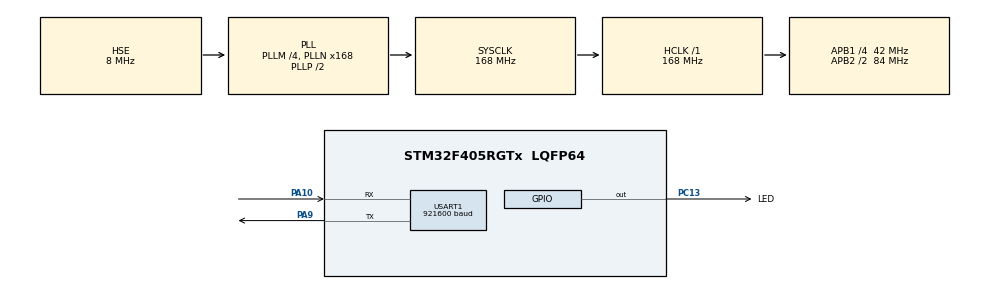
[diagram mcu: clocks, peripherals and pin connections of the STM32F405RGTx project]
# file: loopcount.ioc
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Mcu.Family=STM32F4
Mcu.Name=STM32F405RGTx
Mcu.Package=LQFP64
NVIC.PriorityGroup=NVIC_PRIORITYGROUP_4
NVIC.USART1_IRQn=true\:0\:0\:false\:false\:true\:true\:true
PA10.Mode=Asynchronous
PA10.Signal=USART1_RX
PA13.Mode=Serial_Wire
PA13.Signal=SYS_JTMS-SWDIO
PA14.Mode=Serial_Wire
PA14.Signal=SYS_JTCK-SWCLK
PA9.Mode=Asynchronous
PA9.Signal=USART1_TX
PC13-ANTI_TAMP.GPIO_Label=LED
PC13-ANTI_TAMP.GPIO_ModeDefaultOutputPP=GPIO_MODE_OUTPUT_OD
PC13-ANTI_TAMP.PinState=GPIO_PIN_SET
PC13-ANTI_TAMP.Signal=GPIO_Output
PH0-OSC_IN.Mode=HSE-External-Oscillator
PH0-OSC_IN.Signal=RCC_OSC_IN
PH1-OSC_OUT.Mode=HSE-External-Oscillator
PH1-OSC_OUT.Signal=RCC_OSC_OUT
ProjectManager.HeapSize=0x200
ProjectManager.StackSize=0x400
ProjectManager.TargetToolchain=STM32CubeIDE
RCC.48MHZClocksFreq_Value=84000000
RCC.AHBFreq_Value=168000000
RCC.APB1CLKDivider=RCC_HCLK_DIV4
RCC.APB1Freq_Value=42000000
RCC.APB1TimFreq_Value=84000000
RCC.APB2CLKDivider=RCC_HCLK_DIV2
RCC.APB2Freq_Value=84000000
RCC.APB2TimFreq_Value=168000000
RCC.CortexFreq_Value=168000000
RCC.DATA_CACHE_ENABLE=1
RCC.HCLKFreq_Value=168000000
RCC.HSE_VALUE=8000000
RCC.HSI_VALUE=16000000
RCC.INSTRUCTION_CACHE_ENABLE=1
RCC.LSE_VALUE=32768
RCC.PLLM=4
RCC.PLLN=168
RCC.PLLSourceVirtual=RCC_PLLSOURCE_HSE
RCC.PREFETCH_ENABLE=1
RCC.SYSCLKFreq_VALUE=168000000
RCC.SYSCLKSource=RCC_SYSCLKSOURCE_PLLCLK
RCC.VCOOutputFreq_Value=336000000
USART1.BaudRate=921600
USART1.VirtualMode=VM_ASYNC
board=custom

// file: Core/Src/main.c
/* USER CODE BEGIN Header */
/**
  ******************************************************************************
  * @file           : main.c
  * @brief          : Main program body
  ******************************************************************************
  * @attention
  *
  * <h2><center>&copy; Copyright (c) 2021 STMicroelectronics.
  * All rights reserved.</center></h2>
  *
  * This software component is licensed by ST under BSD 3-Clause license,
  * the "License"; You may not use this file except in compliance with the
  * License. You may obtain a copy of the License at:
  *                        opensource.org/licenses/BSD-3-Clause
  *
  ******************************************************************************
  */
/* USER CODE END Header */
#include "main.h"

/* USER CODE BEGIN Includes */
#include "stdio.h"
/* USER CODE END Includes */

UART_HandleTypeDef huart1;

void SystemClock_Config(void);
static void MX_GPIO_Init(void);
static void MX_USART1_UART_Init(void);

/* USER CODE BEGIN 0 */
// Send printf to uart1

int _write(int fd, char* ptr, int len) {
  HAL_StatusTypeDef hstatus;

  if (fd == 1 || fd == 2) {
    hstatus = HAL_UART_Transmit(&huart1, (uint8_t *) ptr, len, HAL_MAX_DELAY);
    if (hstatus == HAL_OK)
      return len;
    else
      return -1;
  }
  return -1;
}

/* USER CODE END 0 */

int main(void)
{

  /* MCU Configuration--------------------------------------------------------*/

  /* Reset of all peripherals, Initializes the Flash interface and the Systick. */
  HAL_Init();

  /* Configure the system clock */
  SystemClock_Config();

  /* Initialize all configured peripherals */
  MX_GPIO_Init();
  MX_USART1_UART_Init();
  /* USER CODE BEGIN 2 */
  printf("Loopcount start!\n");
  /* USER CODE END 2 */

  /* Infinite loop */
  /* USER CODE BEGIN WHILE */

  uint32_t last_print = 0, now = 0, cnt = 0;

  for (;;)
  {

	now = HAL_GetTick();
	if (now - last_print > 1000) {
		printf("Tick %lu - count = %lu\n", now / 1000, cnt);
		HAL_GPIO_TogglePin(LED_GPIO_Port, LED_Pin);
		cnt = 0;

		last_print = now;
	}

	cnt++;
    /* USER CODE END WHILE */

  }
}

void SystemClock_Config(void)
{
  RCC_OscInitTypeDef RCC_OscInitStruct = {0};
  RCC_ClkInitTypeDef RCC_ClkInitStruct = {0};

  /** Configure the main internal regulator output voltage
  */
  __HAL_RCC_PWR_CLK_ENABLE();
  __HAL_PWR_VOLTAGESCALING_CONFIG(PWR_REGULATOR_VOLTAGE_SCALE1);
  /** Initializes the RCC Oscillators according to the specified parameters
  * in the RCC_OscInitTypeDef structure.
  */
  RCC_OscInitStruct.OscillatorType = RCC_OSCILLATORTYPE_HSE;
  RCC_OscInitStruct.HSEState = RCC_HSE_ON;
  RCC_OscInitStruct.PLL.PLLState = RCC_PLL_ON;
  RCC_OscInitStruct.PLL.PLLSource = RCC_PLLSOURCE_HSE;
  RCC_OscInitStruct.PLL.PLLM = 4;
  RCC_OscInitStruct.PLL.PLLN = 168;
  RCC_OscInitStruct.PLL.PLLP = RCC_PLLP_DIV2;
  RCC_OscInitStruct.PLL.PLLQ = 4;
  if (HAL_RCC_OscConfig(&RCC_OscInitStruct) != HAL_OK)
  {
    Error_Handler();
  }
  /** Initializes the CPU, AHB and APB buses clocks
  */
  RCC_ClkInitStruct.ClockType = RCC_CLOCKTYPE_HCLK|RCC_CLOCKTYPE_SYSCLK
                              |RCC_CLOCKTYPE_PCLK1|RCC_CLOCKTYPE_PCLK2;
  RCC_ClkInitStruct.SYSCLKSource = RCC_SYSCLKSOURCE_PLLCLK;
  RCC_ClkInitStruct.AHBCLKDivider = RCC_SYSCLK_DIV1;
  RCC_ClkInitStruct.APB1CLKDivider = RCC_HCLK_DIV4;
  RCC_ClkInitStruct.APB2CLKDivider = RCC_HCLK_DIV2;

  if (HAL_RCC_ClockConfig(&RCC_ClkInitStruct, FLASH_LATENCY_5) != HAL_OK)
  {
    Error_Handler();
  }
}

static void MX_USART1_UART_Init(void)
{

  huart1.Instance = USART1;
  huart1.Init.BaudRate = 921600;
  huart1.Init.WordLength = UART_WORDLENGTH_8B;
  huart1.Init.StopBits = UART_STOPBITS_1;
  huart1.Init.Parity = UART_PARITY_NONE;
  huart1.Init.Mode = UART_MODE_TX_RX;
  huart1.Init.HwFlowCtl = UART_HWCONTROL_NONE;
  huart1.Init.OverSampling = UART_OVERSAMPLING_16;
  if (HAL_UART_Init(&huart1) != HAL_OK)
  {
    Error_Handler();
  }

}

static void MX_GPIO_Init(void)
{
  GPIO_InitTypeDef GPIO_InitStruct = {0};

  /* GPIO Ports Clock Enable */
  __HAL_RCC_GPIOC_CLK_ENABLE();
  __HAL_RCC_GPIOH_CLK_ENABLE();
  __HAL_RCC_GPIOA_CLK_ENABLE();

  /*Configure GPIO pin Output Level */
  HAL_GPIO_WritePin(LED_GPIO_Port, LED_Pin, GPIO_PIN_SET);

  /*Configure GPIO pin : LED_Pin */
  GPIO_InitStruct.Pin = LED_Pin;
  GPIO_InitStruct.Mode = GPIO_MODE_OUTPUT_OD;
  GPIO_InitStruct.Pull = GPIO_NOPULL;
  GPIO_InitStruct.Speed = GPIO_SPEED_FREQ_LOW;
  HAL_GPIO_Init(LED_GPIO_Port, &GPIO_InitStruct);

}

void Error_Handler(void)
{
  __disable_irq();
  while (1)
  {
  }
}

/************************ (C) COPYRIGHT STMicroelectronics *****END OF FILE****/
